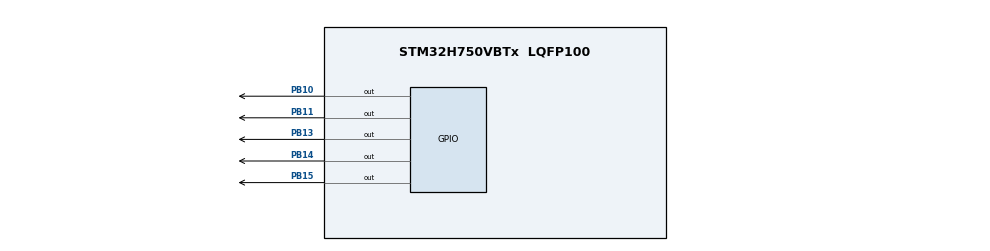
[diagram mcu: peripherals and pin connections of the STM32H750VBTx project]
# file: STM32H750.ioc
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Mcu.Family=STM32H7
Mcu.Name=STM32H750VBTx
Mcu.Package=LQFP100
NVIC.PriorityGroup=NVIC_PRIORITYGROUP_4
PB10.Signal=GPIO_Output
PB11.Signal=GPIO_Output
PB13.Signal=GPIO_Output
PB14.Signal=GPIO_Output
PB15.Signal=GPIO_Output
ProjectManager.HeapSize=0x200
ProjectManager.StackSize=0x400
ProjectManager.TargetToolchain=STM32CubeIDE
RCC.ADCFreq_Value=129000000
RCC.APB1Freq_Value=64000000
RCC.APB2Freq_Value=64000000
RCC.APB3Freq_Value=64000000
RCC.APB4Freq_Value=64000000
RCC.CortexFreq_Value=64000000
RCC.HCLKFreq_Value=64000000
RCC.SYSCLKFreq_VALUE=64000000
RCC.USBFreq_Value=129000000
board=custom

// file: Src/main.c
/* USER CODE BEGIN Header */
/**
  ******************************************************************************
  * @file           : main.c
  * @brief          : Main program body
  ******************************************************************************
  * @attention
  *
  * <h2><center>&copy; Copyright (c) 2019 STMicroelectronics.
  * All rights reserved.</center></h2>
  *
  * This software component is licensed by ST under BSD 3-Clause license,
  * the "License"; You may not use this file except in compliance with the
  * License. You may obtain a copy of the License at:
  *                        opensource.org/licenses/BSD-3-Clause
  *
  ******************************************************************************
  */
/* USER CODE END Header */

#include "main.h"

/* USER CODE BEGIN Includes */
#include "max7219.h"
/* USER CODE END Includes */

void SystemClock_Config(void);
static void MX_GPIO_Init(void);

int main(void)
{

  /* MCU Configuration--------------------------------------------------------*/

  /* Reset of all peripherals, Initializes the Flash interface and the Systick. */
  HAL_Init();

  /* Configure the system clock */
  SystemClock_Config();

  /* Initialize all configured peripherals */
  MX_GPIO_Init();
  /* USER CODE BEGIN 2 */
  max7219_init();
  max7219_clear();
  //max7219_8x8led_display_message("abcdefghijklmnopqrstuvwxyzABCDEFGHIJKLMNOPQRSTUVWXYZ0123456789-_.:,;+!#$%&/()=?", 100);
  max7219_8x8led_display_message("STM32H750VBT6 8x8 LED Matrix    ");
  /* USER CODE END 2 */

  /* Infinite loop */
  while (1)
  {

    /* USER CODE BEGIN 3 */
	  HAL_GPIO_TogglePin(GPIOB, GPIO_PIN_10);
	  HAL_Delay(100);
	  HAL_GPIO_TogglePin(GPIOB, GPIO_PIN_11);
	  max7219_8x8led_shift_message(1);
	  max7219_8x8led_showBuffer();

  }
  /* USER CODE END 3 */
}

void SystemClock_Config(void)
{
  RCC_OscInitTypeDef RCC_OscInitStruct = {0};
  RCC_ClkInitTypeDef RCC_ClkInitStruct = {0};

  /** Supply configuration update enable
  */
  HAL_PWREx_ConfigSupply(PWR_LDO_SUPPLY);
  /** Configure the main internal regulator output voltage
  */
  __HAL_PWR_VOLTAGESCALING_CONFIG(PWR_REGULATOR_VOLTAGE_SCALE3);

  while(!__HAL_PWR_GET_FLAG(PWR_FLAG_VOSRDY)) {}
  /** Initializes the CPU, AHB and APB busses clocks
  */
  RCC_OscInitStruct.OscillatorType = RCC_OSCILLATORTYPE_HSI;
  RCC_OscInitStruct.HSIState = RCC_HSI_DIV1;
  RCC_OscInitStruct.HSICalibrationValue = RCC_HSICALIBRATION_DEFAULT;
  RCC_OscInitStruct.PLL.PLLState = RCC_PLL_NONE;
  if (HAL_RCC_OscConfig(&RCC_OscInitStruct) != HAL_OK)
  {
    Error_Handler();
  }
  /** Initializes the CPU, AHB and APB busses clocks
  */
  RCC_ClkInitStruct.ClockType = RCC_CLOCKTYPE_HCLK|RCC_CLOCKTYPE_SYSCLK
                              |RCC_CLOCKTYPE_PCLK1|RCC_CLOCKTYPE_PCLK2
                              |RCC_CLOCKTYPE_D3PCLK1|RCC_CLOCKTYPE_D1PCLK1;
  RCC_ClkInitStruct.SYSCLKSource = RCC_SYSCLKSOURCE_HSI;
  RCC_ClkInitStruct.SYSCLKDivider = RCC_SYSCLK_DIV1;
  RCC_ClkInitStruct.AHBCLKDivider = RCC_HCLK_DIV1;
  RCC_ClkInitStruct.APB3CLKDivider = RCC_APB3_DIV1;
  RCC_ClkInitStruct.APB1CLKDivider = RCC_APB1_DIV1;
  RCC_ClkInitStruct.APB2CLKDivider = RCC_APB2_DIV1;
  RCC_ClkInitStruct.APB4CLKDivider = RCC_APB4_DIV1;

  if (HAL_RCC_ClockConfig(&RCC_ClkInitStruct, FLASH_LATENCY_0) != HAL_OK)
  {
    Error_Handler();
  }
}

static void MX_GPIO_Init(void)
{
  GPIO_InitTypeDef GPIO_InitStruct = {0};

  /* GPIO Ports Clock Enable */
  __HAL_RCC_GPIOB_CLK_ENABLE();

  /*Configure GPIO pin Output Level */
  HAL_GPIO_WritePin(GPIOB, GPIO_PIN_10|GPIO_PIN_11|GPIO_PIN_13|GPIO_PIN_14
                          |GPIO_PIN_15, GPIO_PIN_RESET);

  /*Configure GPIO pins : PB10 PB11 PB13 PB14
                           PB15 */
  GPIO_InitStruct.Pin = GPIO_PIN_10|GPIO_PIN_11|GPIO_PIN_13|GPIO_PIN_14
                          |GPIO_PIN_15;
  GPIO_InitStruct.Mode = GPIO_MODE_OUTPUT_PP;
  GPIO_InitStruct.Pull = GPIO_NOPULL;
  GPIO_InitStruct.Speed = GPIO_SPEED_FREQ_LOW;
  HAL_GPIO_Init(GPIOB, &GPIO_InitStruct);

}

void Error_Handler(void)
{
}

/************************ (C) COPYRIGHT STMicroelectronics *****END OF FILE****/
